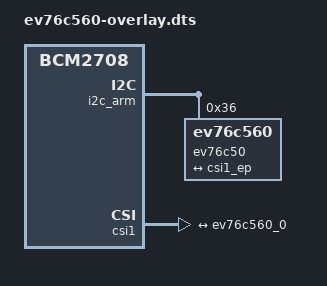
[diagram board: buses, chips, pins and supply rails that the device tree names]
// Definitions for EV76C560 camera module on ARM I2C bus
/dts-v1/;
/plugin/;

/{
	compatible = "brcm,bcm2708";

	fragment@0 {
		target = <&i2c_arm>;
		__overlay__ {
			#address-cells = <1>;
			#size-cells = <0>;
			status = "okay";

			ev76c50: ev76c560@36 {
				compatible = "ev76c560";
				reg = <0x36>;
				status = "okay";

				port {
					ev76c560_0: endpoint {
						remote-endpoint = <&csi1_ep>;
						clock-lanes = <0>;
						data-lanes = <1 2>;
						link-frequencies =
							/bits/ 64 <297000000>;
					};
				};
			};
		};
	};

	fragment@1 {
		target = <&csi1>;
		__overlay__ {
			#address-cells = <1>;
			#size-cells = <0>;
			status = "okay";

			port {
				csi1_ep: endpoint {
					remote-endpoint = <&ev76c560_0>;
				};
			};
		};
	};
};
